# EFR32FG25B222F1920IM56 register map
Vendor: Silicon Labs; Series: EFR32; File version: B
Registers are 32-bit, read-write, reset 0x0 unless marked. A register's access mark holds for its fields unless they carry their own. Offsets are from the block's base; [hi:lo] are bit positions; {n}, {i} and the like mark numbered series; 'fields as' and 'values as' point back to an identical list.

## USBAHB_NS_AHBS — USBAHB_NS_AHBS Registers
Base 0x56000000
Same registers: USBAHB_S_AHBS 0x46000000
0x00 GOTGCTL reset 0x10000
  [21] CURMOD ro — Current Mode of Operation
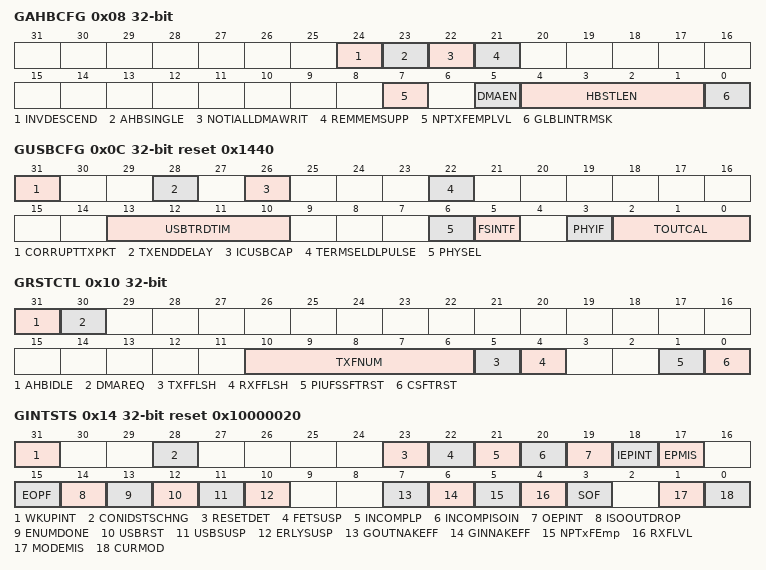
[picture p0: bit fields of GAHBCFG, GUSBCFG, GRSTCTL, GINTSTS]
0x08 GAHBCFG
  [24] INVDESCEND — Inverse Descriptor Endianness
  [23] AHBSINGLE — AHB Single Support
  [22] NOTIALLDMAWRIT — Notify All Dma Write Trans
  [21] REMMEMSUPP — Remote Memory Support
  [7] NPTXFEMPLVL — Non-Periodic TxFIFO Empty Level
  [5] DMAEN — DMA Enable
  [4:1] HBSTLEN — Burst Length/Type
  [0] GLBLINTRMSK — Global Interrupt Mask
0x0C GUSBCFG reset 0x1440
  [31] CORRUPTTXPKT wo — corrupt tx packet
  [28] TXENDDELAY
  [26] ICUSBCAP ro — IC_USB-Capable
  [22] TERMSELDLPULSE — TermSel DLine Pulsing Selection
  [13:10] USBTRDTIM — USB turnaround time
  [6] PHYSEL — "2.0 HS sel or 1.1 FS sel
  [5] FSINTF — Full-Speed Serial Interface Sel
  [3] PHYIF — PHY Interface
  [2:0] TOUTCAL — HS/FS Timeout cal
0x10 GRSTCTL
  [31] AHBIDLE ro — AHB Master Idle
  [30] DMAREQ ro — DMA Request Signal
  [10:6] TXFNUM — TxFIFO Number
  [5] TXFFLSH — TxFIFO Flush
  [4] RXFFLSH — RxFIFO Flush
  [1] PIUFSSFTRST — PIU FS Dedicated Controller Sft rst
  [0] CSFTRST — Core Soft Reset
0x14 GINTSTS reset 0x10000020
  [31] WKUPINT — Resume/Remote Wakeup Detected Irq
  [28] CONIDSTSCHNG — Connector ID Status Change
  [23] RESETDET — Reset detected Interrupt
  [22] FETSUSP — Data Fetch Suspended
  [21] INCOMPLP ro — Incomplete Periodic Transfer
  [20] INCOMPISOIN ro — Incomplete Isochronous IN Transfer
  [19] OEPINT ro — OUT Endpoints Interrupt
  [18] IEPINT ro — IN Endpoints Interrupt
  [17] EPMIS — Endpoint Mismatch Interrupt
  [15] EOPF — End of Periodic Frame Interrupt
  [14] ISOOUTDROP — Iso OUT Packet Dropped IRQ
  [13] ENUMDONE — Enumeration Done
  [12] USBRST — USB Reset
  [11] USBSUSP — USB Suspend
  [10] ERLYSUSP — Early Suspend
  [7] GOUTNAKEFF ro — Global OUT NAK Effective
  [6] GINNAKEFF ro — Global IN Non-periodic NAK Effective
  [5] NPTxFEmp ro — Non periodic TXFIFO Empty
  [4] RXFLVL ro — RxFIFO Non-Empty
  [3] SOF — tart of (micro)Frame
  [1] MODEMIS — Mode Mismatch Interrupt
  [0] CURMOD ro — Current Mode of Operation
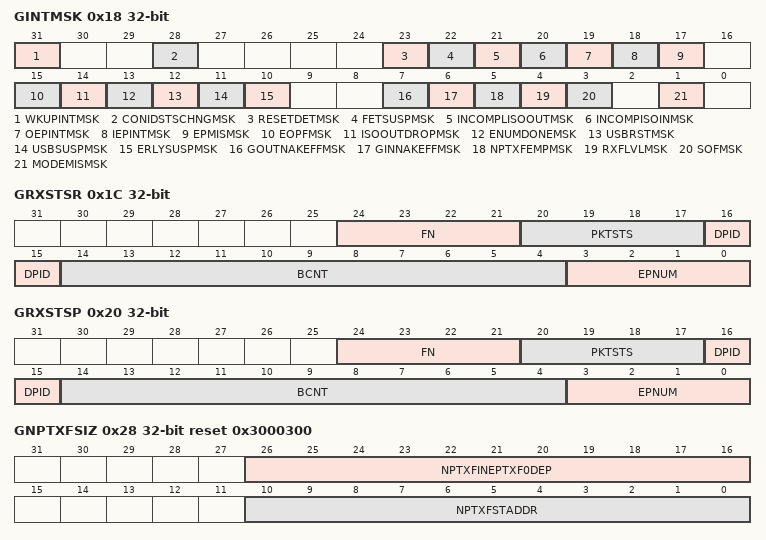
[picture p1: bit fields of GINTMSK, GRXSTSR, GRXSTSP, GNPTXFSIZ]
0x18 GINTMSK
  [31] WKUPINTMSK — Resume/Remote WkUp Det Irq Mask
  [28] CONIDSTSCHNGMSK — Connector ID Status Change Mask
  [23] RESETDETMSK — Reset detected Interrupt Mask
  [22] FETSUSPMSK — Data Fetch Suspended Mask
  [21] INCOMPLISOOUTMSK — Incomp Iso OUT Transfer Mask
  [20] INCOMPISOINMSK — Incomp Iso IN Transfer Mask
  [19] OEPINTMSK — OUT Endpoints Interrupt Mask
  [18] IEPINTMSK — IN Endpoints Interrupt Mask
  [17] EPMISMSK — Endpoint Mismatch Interrupt Mask
  [15] EOPFMSK — End of Periodic Frame Irq Mask
  [14] ISOOUTDROPMSK — Iso OUT Pkt Dropped IRQ Mask
  [13] ENUMDONEMSK — Enumeration Done Mask
  [12] USBRSTMSK — USB Reset Mask
  [11] USBSUSPMSK — USB Suspend Mask
  [10] ERLYSUSPMSK — Early Suspend Mask
  [7] GOUTNAKEFFMSK — Global OUT NAK Effective Mask
  [6] GINNAKEFFMSK — Global Non-per IN NAK Eff Mask
  [5] NPTXFEMPMSK — NP TXFIFO Empty Msk
  [4] RXFLVLMSK — Receive FIFO Non-Empty Mask
  [3] SOFMSK — Start of (micro)Frame Mask
  [1] MODEMISMSK — Mode Mismatch Interrupt Mask
0x1C GRXSTSR ro
  [24:21] FN — Frame Number
  [20:17] PKTSTS — Packet Status
  [16:15] DPID — Data PID
  [14:4] BCNT — Byte Count
  [3:0] EPNUM — End Point Num
0x20 GRXSTSP ro
  [24:21] FN — Frame Number
  [20:17] PKTSTS — Packet Status
  [16:15] DPID — Data PID
  [14:4] BCNT — Byte Count
  [3:0] EPNUM — Endpoint Number
0x24 GRXFSIZ reset 0x300
  [9:0] RXFDEP — RxFIFO Depth
0x28 GNPTXFSIZ reset 0x3000300
  [26:16] NPTXFINEPTXF0DEP — IN Endpoint TxFIFO 0 Depth
  [10:0] NPTXFSTADDR — IN EP FIFO0 xmit RAM Start Addr
0x40 GSNPSID ro reset 0x4F54330A
  [31:0] SYNOPSYSID — SNPS ID
0x44 GHWCFG1 ro
  [31:0] EPDIR — User HW Config1 Register
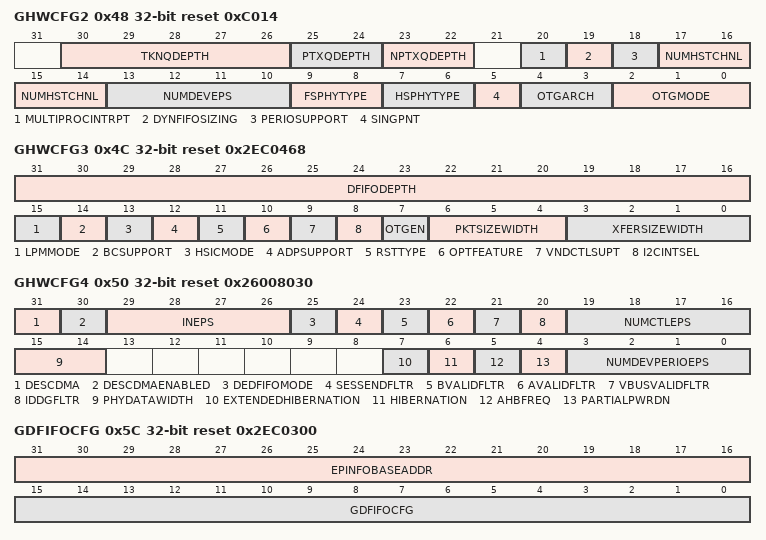
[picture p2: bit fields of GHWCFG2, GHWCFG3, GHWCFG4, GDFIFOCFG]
0x48 GHWCFG2 ro reset 0xC014
  [30:26] TKNQDEPTH — Device Mode IN Token Seq Queue Depth
  [25:24] PTXQDEPTH — Host Mode Periodic Req Queue Dept
  [23:22] NPTXQDEPTH — Non-periodic Request Queue Depth
  [20] MULTIPROCINTRPT — Multi Processor Interrupt Enabled
  [19] DYNFIFOSIZING — Dynamic FIFO Sizing Enabled
  [18] PERIOSUPPORT — Per OUT Chan Supported in Host Mode
  [17:14] NUMHSTCHNL — Number of Host Channels
  [13:10] NUMDEVEPS — Number of Device Endpoints
  [9:8] FSPHYTYPE — Full-Speed PHY Interface Type
  [7:6] HSPHYTYPE — New BitField
  [5] SINGPNT — Point-to-Point
  [4:3] OTGARCH — Architecture
  [2:0] OTGMODE — New BitField
0x4C GHWCFG3 ro reset 0x2EC0468
  [31:16] DFIFODEPTH — FIFO depth
  [15] LPMMODE — New BitField
  [14] BCSUPPORT — New BitField
  [13] HSICMODE — New BitField
  [12] ADPSUPPORT — New BitField
  [11] RSTTYPE — Reset Style For Clocked always
  [10] OPTFEATURE — Optional Features Removed
  [9] VNDCTLSUPT — Vendor Control Interface Support
  [8] I2CINTSEL — I2C Selection
  [7] OTGEN — OTG Function Enabled
  [6:4] PKTSIZEWIDTH — Width of Packet Size Counters
  [3:0] XFERSIZEWIDTH — Width of Transfer Size Counters
0x50 GHWCFG4 ro reset 0x26008030
  [31] DESCDMA — New BitField
  [30] DESCDMAENABLED — New BitField
  [29:26] INEPS — Num Device Mode IN EPs inc Ctrl EPs
  [25] DEDFIFOMODE — Dedicated xmit FIFO For device IN EPs
  [24] SESSENDFLTR — New BitField
  [23] BVALIDFLTR — New BitField
  [22] AVALIDFLTR — New BitField
  [21] VBUSVALIDFLTR — New BitField
  [20] IDDGFLTR — New BitField
  [19:16] NUMCTLEPS — New BitField
  [15:14] PHYDATAWIDTH — New BitField
  [7] EXTENDEDHIBERNATION — New BitField
  [6] HIBERNATION — New BitField
  [5] AHBFREQ — AHB Frequency
  [4] PARTIALPWRDN — New BitField
  [3:0] NUMDEVPERIOEPS — Dev Mode Periodic IN EPs
0x5C GDFIFOCFG reset 0x2EC0300
  [31:16] EPINFOBASEADDR — New BitField
  [15:0] GDFIFOCFG — New BitField
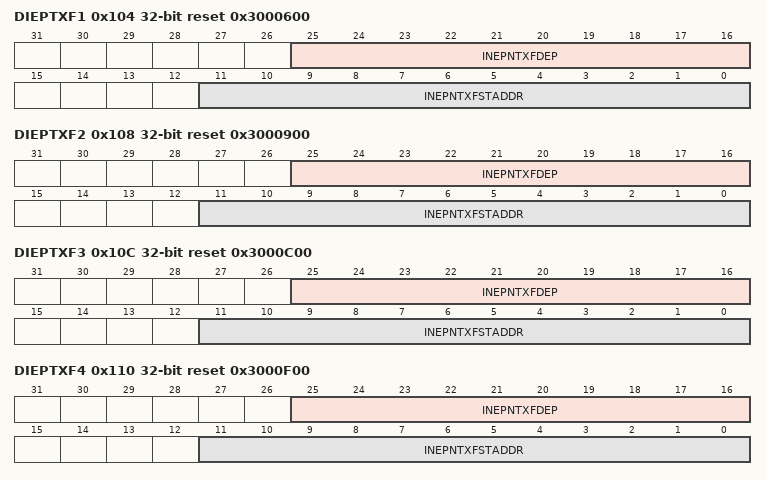
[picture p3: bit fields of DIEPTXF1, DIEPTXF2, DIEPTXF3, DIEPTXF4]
0x104 DIEPTXF1 reset 0x3000600
  [25:16] INEPNTXFDEP — IN Endpoint TxFIFO Depth
  [11:0] INEPNTXFSTADDR — IN EP FIFOn xmit RAM Start Addr
0x108 DIEPTXF2 reset 0x3000900
  fields as DIEPTXF1
0x10C DIEPTXF3 reset 0x3000C00
  fields as DIEPTXF1
0x110 DIEPTXF4 reset 0x3000F00
  fields as DIEPTXF1
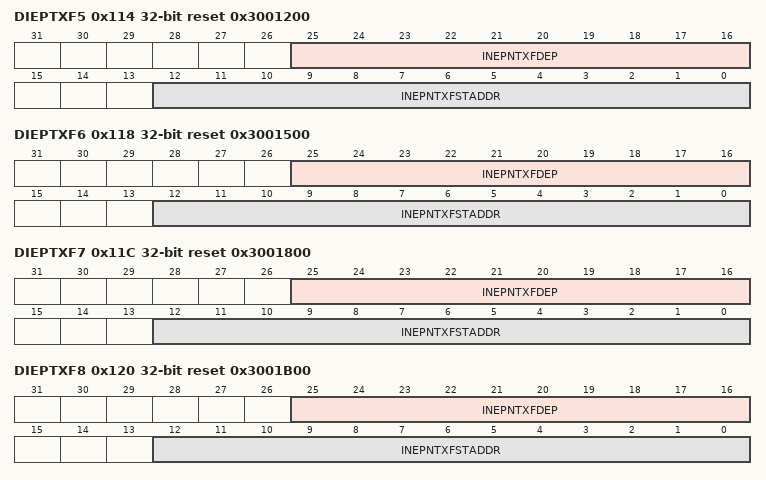
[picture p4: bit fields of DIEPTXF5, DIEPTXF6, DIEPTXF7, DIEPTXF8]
0x114 DIEPTXF5 reset 0x3001200
  [25:16] INEPNTXFDEP — IN Endpoint TxFIFO Depth
  [12:0] INEPNTXFSTADDR — IN EP FIFOn xmit RAM Start Addr
0x118 DIEPTXF6 reset 0x3001500
  fields as DIEPTXF5
0x11C DIEPTXF7 reset 0x3001800
  fields as DIEPTXF5
0x120 DIEPTXF8 reset 0x3001B00
  fields as DIEPTXF5
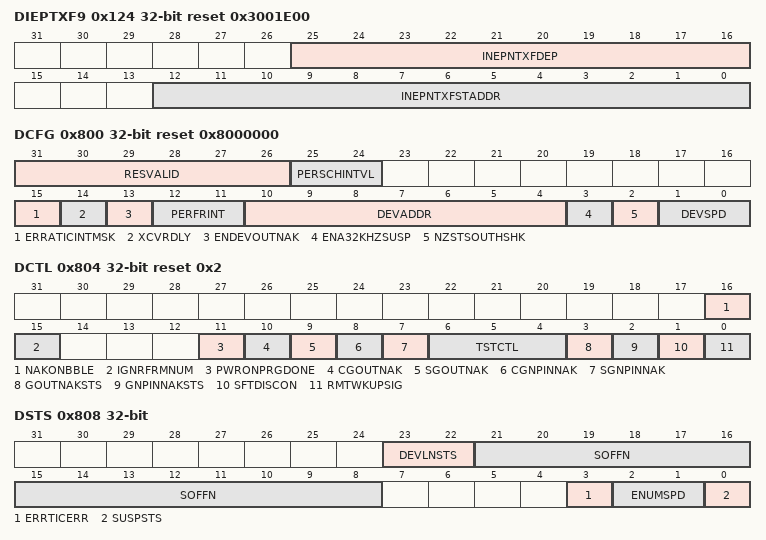
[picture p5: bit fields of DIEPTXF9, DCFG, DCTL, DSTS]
0x124 DIEPTXF9 reset 0x3001E00
  fields as DIEPTXF5
0x800 DCFG reset 0x8000000
  [31:26] RESVALID — Resume VAlidation Period
  [25:24] PERSCHINTVL — Periodic Scheduling Interval
  [15] ERRATICINTMSK
  [14] XCVRDLY
  [13] ENDEVOUTNAK — Enable Device out of NAK
  [12:11] PERFRINT — Periodic Frame Interval
  [10:4] DEVADDR — Device Address
  [3] ENA32KHZSUSP — Enable 32 KHz Suspend mode
  [2] NZSTSOUTHSHK — NZ-Length Status OUT Handshake
  [1:0] DEVSPD — Device Speed
0x804 DCTL reset 0x2
  [16] NAKONBBLE — NAK on Babble Error
  [15] IGNRFRMNUM — Ignore frame num for ISO end points
  [11] PWRONPRGDONE — Power-On Programming Done
  [10] CGOUTNAK wo — Clear Global Out NAK
  [9] SGOUTNAK wo — Set Global Out NAK
  [8] CGNPINNAK wo — Clear Global Non-periodic IN NAK
  [7] SGNPINNAK wo — Set Global Non-periodic in NAK
  [6:4] TSTCTL — TEst Control
  [3] GOUTNAKSTS ro — Global OUT NAK Status
  [2] GNPINNAKSTS ro — Global Non-periodic IN NAK Status
  [1] SFTDISCON — Soft Disconnect
  [0] RMTWKUPSIG — Remote Wakeup Signalling
0x808 DSTS ro
  [23:22] DEVLNSTS — logic level of USB data lines
  [21:8] SOFFN — Frame/u-frameNumber of the recvd SOF
  [3] ERRTICERR — Erratic Error
  [2:1] ENUMSPD — Enumerated Speed
  [0] SUSPSTS — Suspend Status
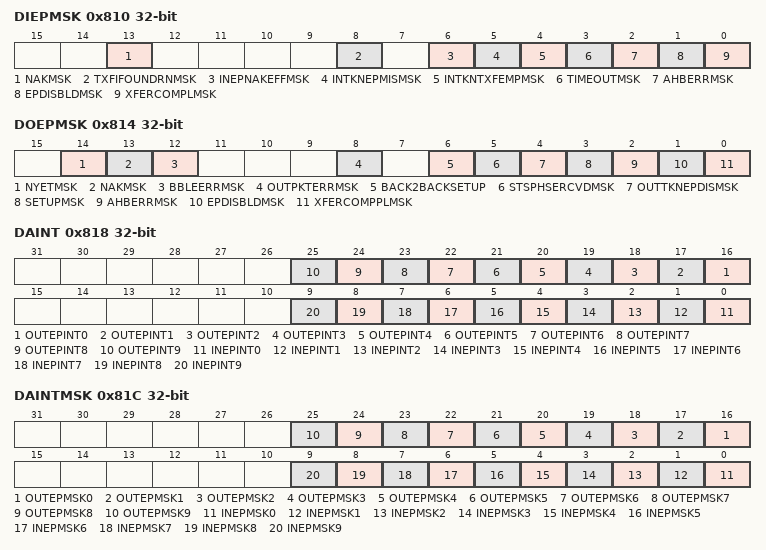
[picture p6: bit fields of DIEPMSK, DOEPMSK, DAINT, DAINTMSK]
0x810 DIEPMSK
  [13] NAKMSK — NAK interrupt Mask
  [8] TXFIFOUNDRNMSK — FIFO Underrun Mask
  [6] INEPNAKEFFMSK — IN Endpoint NAK Effective Mask
  [5] INTKNEPMISMSK — IN Token recvd with EP Mismatch Mask
  [4] INTKNTXFEMPMSK — IN token recvd when FIFO mt irq mask
  [3] TIMEOUTMSK — Timout Condition Mask
  [2] AHBERRMSK — AHB Error Mask
  [1] EPDISBLDMSK — Endpoint Disabled Interrupt Mask
  [0] XFERCOMPLMSK — Transfer Completed Interrupt Mask
0x814 DOEPMSK
  [14] NYETMSK — NYET Interrupt Mask
  [13] NAKMSK — NAK Interrupt Mask
  [12] BBLEERRMSK — Babble Error Interrupt Mask
  [8] OUTPKTERRMSK — OUT Packet Error Mask
  [6] BACK2BACKSETUP — Back-to-Back SETUP Packets recvd Mask
  [5] STSPHSERCVDMSK — Status Phase Received Mask
  [4] OUTTKNEPDISMSK — OUT Token recvd when EP Disabled Mask
  [3] SETUPMSK — Setup Phase Done Mask
  [2] AHBERRMSK — Ahb Error Mask
  [1] EPDISBLDMSK — Endpoint Disabled Interrupt Mask
  [0] XFERCOMPPLMSK — Device OUT EP Common IRQ Mask Register
0x818 DAINT ro
  [n+16] OUTEPINT{n} (n=0..9) — EP{n} OUT IRQ
  [n] INEPINT{n} (n=0..9) — EP{n} IRQ
0x81C DAINTMSK
  [n+16] OUTEPMSK{n} (n=0..9) — OUT EP MASK{n}
  [n] INEPMSK{n} (n=0..9) — IN EP MASK{n}
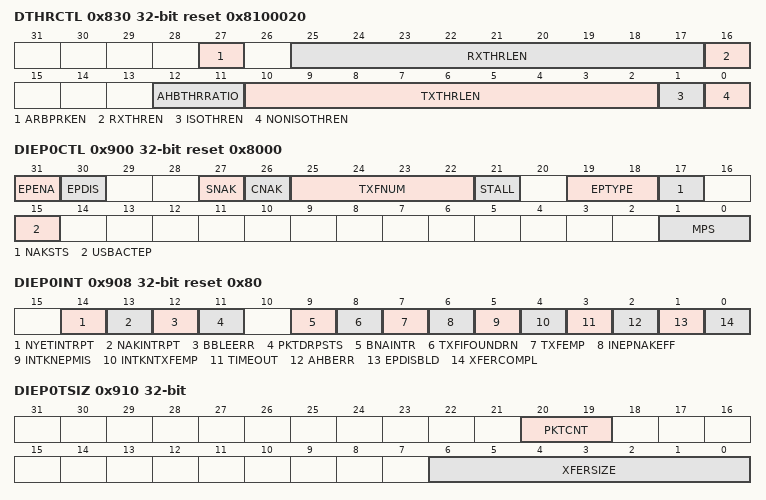
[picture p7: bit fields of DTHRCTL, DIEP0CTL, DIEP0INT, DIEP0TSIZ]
0x830 DTHRCTL reset 0x8100020
  [27] ARBPRKEN — Arbiter Parking Enable
  [25:17] RXTHRLEN — Receive Threshold Length
  [16] RXTHREN — Receive Threshold Enable
  [12:11] AHBTHRRATIO — AHB Threshold Ratio
  [10:2] TXTHRLEN — Transmit threshold length
  [1] ISOTHREN — ISO IN EP Threshold Enable
  [0] NONISOTHREN — Non-ISO IN EP Threshold Enable
0x834 DIEPEMPMSK
  [15:0] DIEPMPMSK — IN EP Tx FIFO Empty IRQ Mask Bits
0x900 DIEP0CTL reset 0x8000
  [31] EPENA — End point enable
  [30] EPDIS — Endpoint Disable
  [27] SNAK wo — Set NAK
  [26] CNAK wo — Clear NAK
  [25:22] TXFNUM — TXFIFO Number
  [21] STALL — Handshake
  [19:18] EPTYPE ro — Endpoint Type
  [17] NAKSTS ro — NAK Status
  [15] USBACTEP ro — USB Active Endpoint
  [1:0] MPS — Maximum packet size
0x908 DIEP0INT reset 0x80
  [14] NYETINTRPT — NYET Interrupt
  [13] NAKINTRPT — NAK Interrupt
  [12] BBLEERR — Babble error
  [11] PKTDRPSTS — Packet Drop Status
  [9] BNAINTR — BNA(Buffer Not Available) IRQ
  [8] TXFIFOUNDRN — FIFO Underrun
  [7] TXFEMP — TX FIFO Empty
  [6] INEPNAKEFF — In Endpoint NAK Effective
  [5] INTKNEPMIS — IN Token recvd with EP Mismatch
  [4] INTKNTXFEMP — In Token recvd when TXFIFO Empty
  [3] TIMEOUT — Condition
  [2] AHBERR — AHB Error
  [1] EPDISBLD — Endpoint Disabled Interrupt
  [0] XFERCOMPL — Transfer Completed Interrupt
0x910 DIEP0TSIZ
  [20:19] PKTCNT — Packet Count
  [6:0] XFERSIZE — Transfer size
0x914 DIEP0DMAADDR
  [31:0] DMAADDR
0x918 DIEP0TXFSTS ro reset 0x300
  [15:0] SPCAVAIL — IN EP TxFIFO Space avail
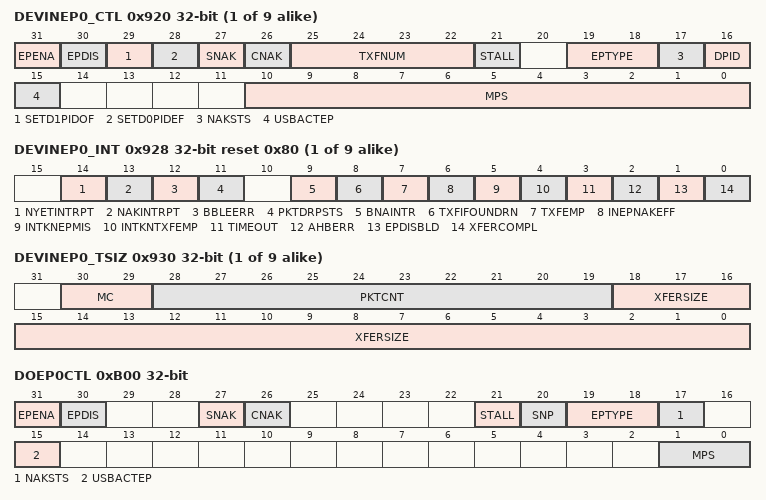
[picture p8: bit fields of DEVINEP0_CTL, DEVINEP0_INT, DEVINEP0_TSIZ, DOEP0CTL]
{0x920+0x20*i} DEVINEP{i}_CTL (i=0..8)
  [31] EPENA — Endpoint enable
  [30] EPDIS — Endpoint Disable
  [29] SETD1PIDOF wo — Set DATA1 PID / odd Frame
  [28] SETD0PIDEF wo — Set DATA0 PID / Even Frame
  [27] SNAK wo — Set NAK
  [26] CNAK wo — Clear NAK
  [25:22] TXFNUM — TxFIFO Number
  [21] STALL — Handshake
  [19:18] EPTYPE — Endpoint Type
  [17] NAKSTS ro — NAK STatus
  [16] DPID ro — Endpoint Data PID, EO_FrNum
  [15] USBACTEP — USB ACtive Endpoint
  [10:0] MPS — Maximum Packet Size
{0x928+0x20*i} DEVINEP{i}_INT reset 0x80 (i=0..8)
  [14] NYETINTRPT — NYET Interrupt
  [13] NAKINTRPT — NAK Interrupt
  [12] BBLEERR — Babble Interrupt
  [11] PKTDRPSTS — Packet Drop Status
  [9] BNAINTR — BNA (Buffer Not Available) IRQ
  [8] TXFIFOUNDRN — FIFO Underrun
  [7] TXFEMP ro — TX FIFO Empty
  [6] INEPNAKEFF — IN Endpoint NAK Effective
  [5] INTKNEPMIS — IN Token recvd with EP Mismatch
  [4] INTKNTXFEMP — IN Token recvd When TxFIFO is Empty
  [3] TIMEOUT — COndition
  [2] AHBERR — AHB Error
  [1] EPDISBLD — Endpoint Disabled IRQ
  [0] XFERCOMPL — Transfer Completed IRQ
{0x930+0x20*i} DEVINEP{i}_TSIZ (i=0..8)
  [30:29] MC — Multi Count
  [28:19] PKTCNT — Packet Count
  [18:0] XFERSIZE — TRansfer Size
{0x934+0x20*i} DEVINEP{i}_DMAADDR (i=0..8)
{0x938+0x20*i} DEVINEP{i}_DTXFSTS ro reset 0x300 (i=0..8)
  [15:0] INEPTXFSPCAVAIL — IN EP TxFIFO Space Avail
0xB00 DOEP0CTL
  [31] EPENA — Endpoint Enable
  [30] EPDIS ro — Endpoint Disable
  [27] SNAK wo — Set NAK
  [26] CNAK wo — Clear NAK
  [21] STALL — Handshake
  [20] SNP — Snoop mode
  [19:18] EPTYPE ro — Endpoint Type
  [17] NAKSTS ro — NAK Status
  [15] USBACTEP ro — US Active Endpoint
  [1:0] MPS ro — Max packet size
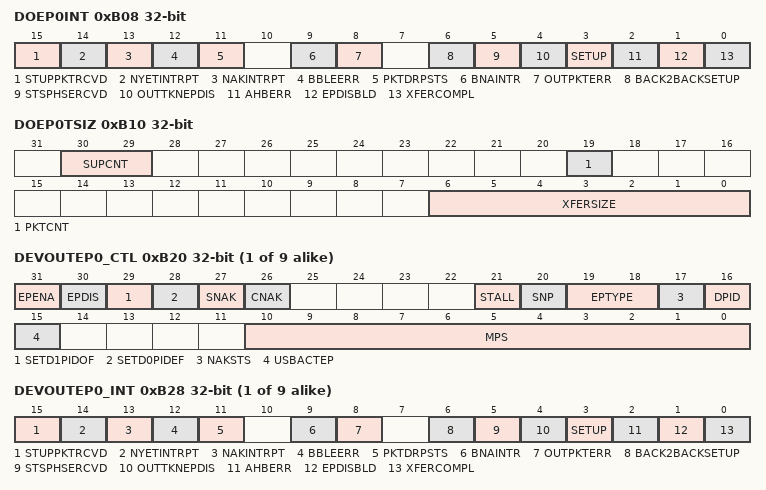
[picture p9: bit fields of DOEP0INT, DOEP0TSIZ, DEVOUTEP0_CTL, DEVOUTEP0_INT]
0xB08 DOEP0INT
  [15] STUPPKTRCVD — Setup Packet Received
  [14] NYETINTRPT — NYET Interrupt
  [13] NAKINTRPT — NAK Interrupt
  [12] BBLEERR — Babble Interrupt
  [11] PKTDRPSTS — Packet Drop Status
  [9] BNAINTR — BNA (Buffer Not Available) IRQ
  [8] OUTPKTERR — OUT Packet Error
  [6] BACK2BACKSETUP — Back-to-Back SETUP Packets recvd
  [5] STSPHSERCVD — Status Phase recvd for ctrl Write
  [4] OUTTKNEPDIS — OUT Token recvd When EP Disabled
  [3] SETUP — Phase Done
  [2] AHBERR — AHB Error
  [1] EPDISBLD — Endpoint Disabled Interrupt
  [0] XFERCOMPL — Transfer Completed Interrupt
0xB10 DOEP0TSIZ
  [30:29] SUPCNT — SETUP Packet Count
  [19] PKTCNT — Packet Count
  [6:0] XFERSIZE — Transfer Size
0xB14 DOEP0DMAADDR
  [31:0] DMAADDR — Device OUT EP 0 DMA addr reg
{0xB20+0x20*i} DEVOUTEP{i}_CTL (i=0..8)
  [31] EPENA — Endpoint Enable
  [30] EPDIS — Endpoint Disable
  [29] SETD1PIDOF wo — Set DATA1 PID, odd fr
  [28] SETD0PIDEF wo — Set DATA0 PID, even fr
  [27] SNAK wo — Set NAK
  [26] CNAK wo — Clear NAK
  [21] STALL — Handshake
  [20] SNP — Snoop Mode
  [19:18] EPTYPE — Endpoint Type
  [17] NAKSTS ro — NAK Status
  [16] DPID ro — Endpoint Data PID
  [15] USBACTEP — USB Active Endpoint
  [10:0] MPS — Maximum Packet Size
{0xB28+0x20*i} DEVOUTEP{i}_INT (i=0..8)
  [15] STUPPKTRCVD — Setup PKT received Interrupt
  [14] NYETINTRPT — NYET Interrupt
  [13] NAKINTRPT — NAK Interrupt
  [12] BBLEERR — Babble Error Interupt
  [11] PKTDRPSTS — Packet Drop Status
  [9] BNAINTR — BNA (Buffer Not Available) IRQ
  [8] OUTPKTERR — OUT Packet Error
  [6] BACK2BACKSETUP — Back-to-Back SETUP Packets recvd
  [5] STSPHSERCVD — Status Phase recvd For ctrl Write
  [4] OUTTKNEPDIS — OUT Token recvd when EP Disabled
  [3] SETUP — Phase Done
  [2] AHBERR — AHB Error
  [1] EPDISBLD — Endpoint Disabled Interrupt
  [0] XFERCOMPL — Transfer Completed Interrupt
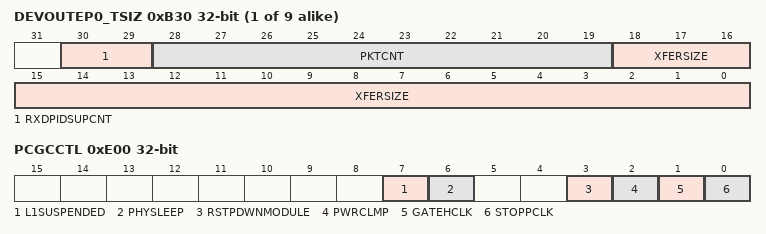
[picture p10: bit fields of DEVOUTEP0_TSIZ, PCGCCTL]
{0xB30+0x20*i} DEVOUTEP{i}_TSIZ (i=0..8)
  [30:29] RXDPIDSUPCNT — rx Data PID/SETUP pkt cnt
  [28:19] PKTCNT — Packet Count
  [18:0] XFERSIZE — Transfer Size
{0xB34+0x20*i} DEVOUTEP{i}_DMAADDR (i=0..8)
  [31:0] DMAADDR — DMA Address
0xE00 PCGCCTL
  [7] L1SUSPENDED ro — New BitField
  [6] PHYSLEEP ro — New BitField
  [3] RSTPDWNMODULE — RST Power-Down Modules
  [2] PWRCLMP — Power Clamp
  [1] GATEHCLK
  [0] STOPPCLK
{0x1000+4i} FIFO0D{i} (i=0..1023)
  [31:0] FIFO0D — EP0 data
{0x2000+4i} FIFO1D{i} (i=0..1023)
  [31:0] FIFO1D — EP1 Data
{0x3000+4i} FIFO2D{i} (i=0..1023)
  [31:0] FIFO2D — EP2 data
{0x4000+4i} FIFO3D{i} (i=0..1023)
  [0] FIFO3D — EP 3 Data
{0x5000+4i} FIFO4D{i} (i=0..1023)
  [31:0] FIFO4D — EP 4 Data
{0x6000+4i} FIFO5D{i} (i=0..1023)
  [0] FIFO5D — EP 5 Data
{0x7000+4i} FIFO6D{i} (i=0..1023)
  [0] FIFO6D — EP 6 Data
{0x8000+4i} FIFO7D{i} (i=0..1023)
  [31:0] FIFO7D — EP 7 Data
{0x9000+4i} FIFO8D{i} (i=0..1023)
  [31:0] FIFO8D — EP 8 Data
{0xA000+4i} FIFO9D{i} (i=0..1023)
  [31:0] FIFO9D — EP 9 Data
{0x20000+4i} FIFORAM{i} (i=0..767)
  [31:0] FIFORAM — FIFORAM direct access
